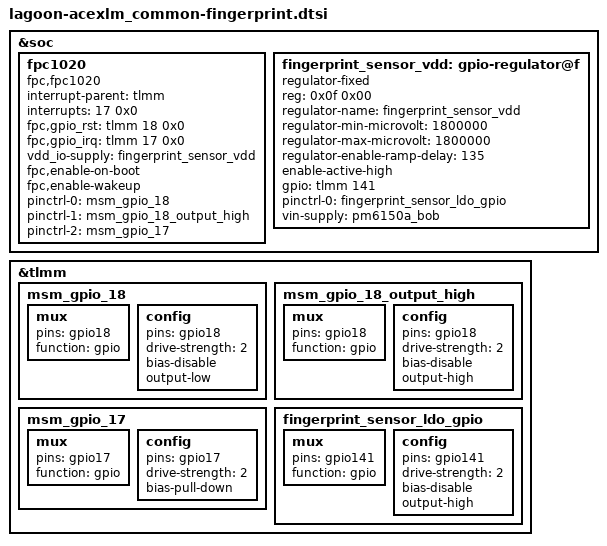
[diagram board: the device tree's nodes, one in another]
// SPDX-License-Identifier: GPL-2.0-only
/*
 * Copyright (c) 2018-2019, The Linux Foundation. All rights reserved.
 */

&soc{

	fpc1020 {
		status = "ok";
		compatible = "fpc,fpc1020";
		interrupt-parent = <&tlmm>;
		interrupts = <17 0x0>;
		fpc,gpio_rst    = <&tlmm 18 0x0>;
		fpc,gpio_irq    = <&tlmm 17 0x0>;
		/*vcc_spi-supply  = <&pm6350_l11>;*/
		vdd_io-supply   = <&fingerprint_sensor_vdd>;
		/*vdd_ana-supply  = <&pm6350_l11>;*/
		fpc,enable-on-boot;
		fpc,enable-wakeup;

		pinctrl-names = "fpc1020_reset_reset",
			"fpc1020_reset_active",
			"fpc1020_irq_active";

		pinctrl-0 = <&msm_gpio_18>;
		pinctrl-1 = <&msm_gpio_18_output_high>;
		pinctrl-2 = <&msm_gpio_17>;
	};

	fingerprint_sensor_vdd: gpio-regulator@f {
		compatible = "regulator-fixed";
		reg = <0x0f 0x00>;
		regulator-name = "fingerprint_sensor_vdd";
		regulator-min-microvolt = <1800000>;
		regulator-max-microvolt = <1800000>;
		regulator-enable-ramp-delay = <135>; // TBD
		enable-active-high;
		gpio = <&tlmm 141 0x00>;
		pinctrl-names = "default";
		pinctrl-0 = <&fingerprint_sensor_ldo_gpio>;
		vin-supply = <&pm6150a_bob>;
	};
};

&tlmm {
	/* GPIO_18 : FP_RESET_N */
	msm_gpio_18: msm_gpio_18 {
		mux {
			 pins = "gpio18";
			 function = "gpio";
		};

		config {
			pins = "gpio18";
			drive-strength = <2>;
			bias-disable;
			output-low;
		};
	};

	/* GPIO_18 : FP_RESET_N, state device active*/
	msm_gpio_18_output_high: msm_gpio_18_output_high {
		mux {
			pins = "gpio18";
			function = "gpio";
		};

		config {
			pins = "gpio18";
			drive-strength = <2>;
			bias-disable;
			output-high;
		};
	};

	/* GPIO_17 : FP_INT_N */
	msm_gpio_17: msm_gpio_17 {
		mux {
			pins = "gpio17";
			function = "gpio";
		};

		config {
			pins = "gpio17";
			drive-strength = <2>;
			bias-pull-down;
		};
	};

	fingerprint_sensor_ldo_gpio: fingerprint_sensor_ldo_gpio {
		mux {
			pins = "gpio141";
			function = "gpio";
		};
		config {
			pins = "gpio141";
			drive-strength = <2>;
			bias-disable;
			output-high;
		};
	};
};
